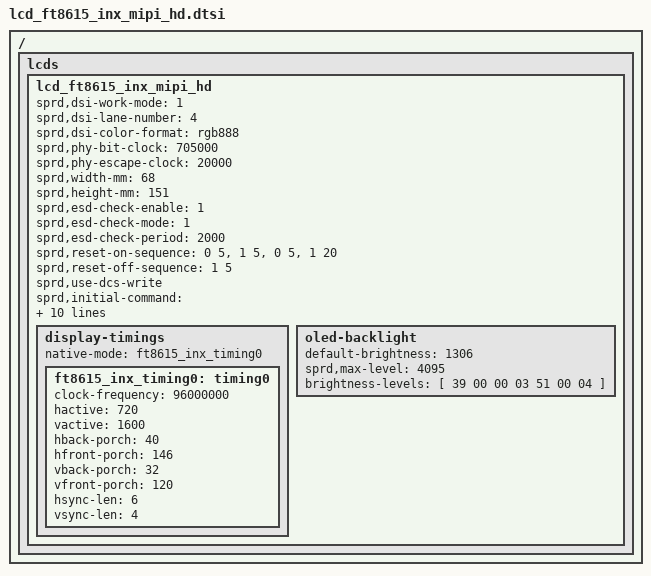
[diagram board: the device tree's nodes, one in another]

/*
 * R61350 Truly LCD config dtsi file for spreadtrum
 *
 * Copyright (C) 2018, Spreadtrum Communications Inc.
 *
 * SPDX-License-Identifier: (GPL-2.0+ OR MIT)
 */

/ {
	fragment {
		target-path = "/";
		__overlay__ {
			lcds {
				lcd_ft8615_inx_mipi_hd: lcd_ft8615_inx_mipi_hd {

					sprd,dsi-work-mode = <1>; /* video burst mode*/
					sprd,dsi-lane-number = <4>;
					sprd,dsi-color-format = "rgb888";

					sprd,phy-bit-clock = <705000>;	/* kbps */
					sprd,phy-escape-clock = <20000>;/* kHz */

					sprd,width-mm = <68>;
					sprd,height-mm = <151>;

					sprd,esd-check-enable = <1>;
					sprd,esd-check-mode = <1>;
					sprd,esd-check-period = <2000>;
					/* sprd,esd-check-register = <0x0A>; */
					/* sprd,esd-check-value = <0x9C>; */

					sprd,reset-on-sequence = <0 5>, <1 5>, <0 5>, <1 20>;
					sprd,reset-off-sequence = <1 5>;

 
					sprd,use-dcs-write;
					sprd,initial-command = [
						39 00 00 02 00 00
						39 00 00 04 FF 87 19 01
						39 00 00 02 00 80
						39 00 00 03 FF 87 19
						39 00 00 02 00 A1
						39 00 00 07 B3 02 D0 06 40 40 F8
						39 00 00 02 00 CA
						39 00 00 02 C0 80
						39 00 00 02 00 80
						39 00 00 09 C2 81 00 01 94 85 01 01 81
						39 00 00 02 00 88
						39 00 00 05 C2 85 01 01 81
						39 00 00 02 00 EA
						39 00 00 05 C2 85 01 01 81
						39 00 00 02 00 90
						39 00 00 09 C2 00 00 01 81 01 00 01 91
						39 00 00 02 00 A0
						39 00 00 10 C2 00 05 00 01 94 01 05 00 01 94 02 05 00 01 94
						39 00 00 02 00 B0
						39 00 00 0B C2 03 05 00 01 94 04 05 00 01 94
						39 00 00 02 00 E0
						39 00 00 07 C2 44 44 40 00 00 00
						39 00 00 02 00 80
						39 00 00 11 CB 00 01 01 01 FD FD 00 FD 03 00 FD 01 00 00 00 03
						39 00 00 02 00 90
						39 00 00 11 CB 00 00 0F 00 0F 0F 00 00 FF 00 00 7F 00 00 00 FF
						39 00 00 02 00 A0
						39 00 00 05 CB 00 00 00 00
						39 00 00 02 00 B0
						39 00 00 05 CB 51 55 E5 55
						39 00 00 02 00 80
						39 00 00 11 CC 00 00 00 00 00 00 00 00 00 00 18 17 16 02 06 07
						39 00 00 02 00 90
						39 00 00 09 CC 08 09 0A 24 25 2A 2A 2A
						39 00 00 02 00 80
						39 00 00 11 CD 00 00 00 00 00 00 00 00 00 00 18 17 16 02 06 07
						39 00 00 02 00 90
						39 00 00 09 CD 08 09 0A 24 25 2A 2A 2A
						39 00 00 02 00 A0
						39 00 00 11 CC 00 00 00 00 00 00 00 00 00 00 18 17 16 02 0A 09
						39 00 00 02 00 B0
						39 00 00 09 CC 08 07 06 24 25 2A 2A 2A
						39 00 00 02 00 A0
						39 00 00 11 CD 00 00 00 00 00 00 00 00 00 00 18 17 16 02 0A 09
						39 00 00 02 00 B0
						39 00 00 09 CD 08 07 06 24 25 2A 2A 2A
						39 00 00 02 00 80
						39 00 00 07 C0 00 AD 00 51 00 10
						39 00 00 02 00 A0
						39 00 00 07 C0 01 76 00 2E 00 10
						39 00 00 02 00 B0
						39 00 00 06 C0 00 AD 01 A8 10
						39 00 00 02 00 C1
						39 00 00 09 C0 00 F6 00 C1 00 A4 01 22
						39 00 00 02 00 D7
						39 00 00 07 C0 00 A4 00 55 00 10
						39 00 00 02 00 A5
						39 00 00 05 C1 00 34 00 02
						39 00 00 02 00 82
						39 00 00 0E CE 01 09 00 9B 00 9B 00 67 00 67 0D 0E 09
						39 00 00 02 00 90
						39 00 00 09 CE 00 82 0D 5C 00 82 80 09
						39 00 00 02 00 A0
						39 00 00 04 CE 00 00 00
						39 00 00 02 00 B0
						39 00 00 04 CE 11 00 00
						39 00 00 02 00 D1
						39 00 00 08 CE 00 0A 01 01 00 42 01
						39 00 00 02 00 E1
						39 00 00 0C CE 08 02 15 02 15 02 15 00 1F 00 46
						39 00 00 02 00 F1
						39 00 00 0A CE 10 08 0B 00 B9 00 B9 00 E2
						39 00 00 02 00 B0
						39 00 00 05 CF 00 00 4D 51
						39 00 00 02 00 B5
						39 00 00 05 CF 03 03 54 58
						39 00 00 02 00 C0
						39 00 00 05 CF 06 06 27 2B
						39 00 00 02 00 C5
						39 00 00 05 CF 00 00 08 0C
						39 00 00 02 00 90
						39 00 00 07 C0 00 AD 00 51 00 10
						39 00 00 02 00 83
						39 00 00 02 A4 23
						39 00 00 02 00 E8
						39 00 00 02 C0 40
						39 00 00 02 00 85
						39 00 00 02 C4 1E
						39 00 00 02 00 00
						39 00 00 29 E1 00 03 07 0E 00 15 1B 21 27 03 30 36 3C 40 F1 44 4B 51 57 2F 5D 66 6E 77 D2 80 85 8A 91 0D 99 A3 B0 B9 5B C6 D9 EB FF 03
						39 00 00 02 00 00
						39 00 00 29 E2 00 04 07 10 00 1D 25 2B 32 03 3B 41 47 4B F1 4F 56 5C 63 2F 68 6C 72 77 D2 80 85 8A 91 0D 99 A3 B0 B9 5B C6 D9 EB FF 03
						39 00 00 02 00 00
						39 00 00 29 E3 00 03 08 0E 00 15 1B 21 29 03 30 36 3C 40 F1 44 4B 51 57 2F 5D 66 6E 77 D2 80 85 8A 91 0D 99 A3 B0 B9 5B C6 D9 EB FF 03
						39 00 00 02 00 00
						39 00 00 29 E4 00 04 08 10 00 1D 25 2B 34 03 3B 41 47 4B F1 4F 56 5C 62 2F 68 6C 72 77 D2 80 85 8A 91 0D 99 A3 B0 B9 5B C6 D9 EB FF 03
						39 00 00 02 00 00
						39 00 00 29 E5 00 03 08 0E 00 15 1B 21 29 04 31 37 3C 41 00 44 4B 51 57 FF 5E 66 6E 77 39 80 85 8A 91 0D 99 A3 B0 B9 5B C6 D9 EB FF 03
						39 00 00 02 00 00
						39 00 00 29 E6 00 04 09 10 01 1D 25 2C 35 04 3D 43 48 4D 00 50 57 5C 62 0C 69 6C 71 78 04 80 84 89 91 7C 99 A3 B0 B9 16 C5 D9 EB FF C5
						39 00 00 02 00 82
						39 00 00 03 C5 50 50
						39 00 00 02 00 86
						39 00 00 02 C5 60
						39 00 00 02 00 84
						39 00 00 03 C5 32 32
						39 00 00 02 00 87
						39 00 00 03 C5 60 0C
						39 00 00 02 00 00
						39 00 00 03 D8 37 37
						39 00 00 02 00 A3
						39 00 00 02 C5 23
						39 00 00 02 00 A9
						39 00 00 02 C5 19
						39 00 00 02 00 B0
						39 00 00 02 F5 00
						39 00 00 02 00 E0
						39 00 00 02 C5 E0
						39 00 00 02 00 86
						39 00 00 07 C0 01 01 01 01 29 07
						39 00 00 02 00 82
						39 00 00 03 A7 11 01
						39 00 00 02 00 B0
						39 00 00 03 F3 01 FE
						39 00 00 02 00 80
						39 00 00 02 A7 03
						39 00 00 02 00 A0
						39 00 00 0D D6 9C AE A1 8E 85 69 66 66 70 75 83 A1
						39 00 00 02 00 B0
						39 00 00 0D D6 7B 82 81 8E 91 89 84 7E 7A 76 72 76
						39 00 00 02 00 C0
						39 00 00 0D D6 8E 9B 8E 83 82 6C 6B 6F 78 7D 84 99
						39 00 00 02 00 D0
						39 00 00 0D D6 7E 81 81 88 8A 87 82 7F 7D 79 79 7B
						39 00 00 02 00 E0
						39 00 00 0D D6 94 8E 81 72 6D 5B 5F 6E 8C 9D 9D B4
						39 00 00 02 00 F0
						39 00 00 0D D6 83 81 81 82 89 87 81 7D 7A 78 7C 83
						39 00 00 02 00 00
						39 00 00 0D D7 80 89 7C 68 62 51 53 6A 77 7F 80 8D
						39 00 00 02 00 10
						39 00 00 0D D7 7F 82 82 7F 89 89 81 7C 7E 7F 7E 7E
						39 00 00 02 91 80
						39 00 00 02 00 CB
						39 00 00 02 C0 50
						39 00 00 02 00 B0
						39 00 00 02 CA 01
						39 00 00 02 00 B2
						39 00 00 02 CA 0C
						39 00 00 02 00 B5
						39 00 00 02 CA 03
						39 00 00 03 51 00 00
						39 00 00 02 55 00
						05 78 00 01 11
						05 00 00 01 29
						39 05 00 02 53 2C
						39 1E 00 02 35 00
						];

					sprd,sleep-in-command = [
						05 14 00 01 28
						05 8C 00 01 10
						39 00 00 02 00 00
						39 00 00 05 F7 5A A5 95 27
						];

					sprd,sleep-out-command = [
						15 78 00 01 11
						15 14 00 01 29
						];

					sprd,cabc-off-command = [
					  23 00 00 02 55 00
					  ];
					sprd,cabc-ui-command = [
					  23 00 00 02 55 01
					  ];
					sprd,cabc-still-image-command = [
					  23 00 00 02 55 02
					  ];
					sprd,cabc-video-command = [
					  23 00 00 02 55 03
					  ];

					display-timings {
						native-mode = <&ft8615_inx_timing0>;

						ft8615_inx_timing0: timing0 {
							clock-frequency = <96000000>;
							hactive = <720>;
							vactive = <1600>;
							hback-porch = <40>;
							hfront-porch = <146>;
							vback-porch = <32>;
							vfront-porch = <120>;
							hsync-len = <6>;
							vsync-len = <4>;
						};
					};

					oled-backlight {
						default-brightness = <1306>;
						sprd,max-level = <4095>;
						brightness-levels = [
						39 00 00 03 51 00 04
						];
					};
				};
			};
		};
	};
};
